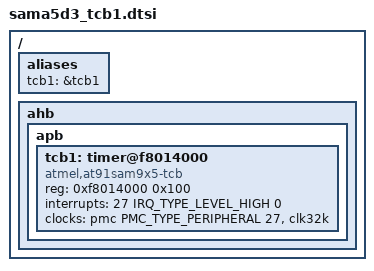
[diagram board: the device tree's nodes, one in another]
// SPDX-License-Identifier: GPL-2.0-only
/*
 * sama5d3_tcb1.dtsi - Device Tree Include file for SAMA5D3 SoC with
 * 2 TC blocks.
 *
 * Copyright (C) 2013 Boris BREZILLON <b.brezillon@overkiz.com>
 */

#include <dt-bindings/pinctrl/at91.h>
#include <dt-bindings/interrupt-controller/irq.h>
#include <dt-bindings/clock/at91.h>

/ {
	aliases {
		tcb1 = &tcb1;
	};

	ahb {
		apb {
			tcb1: timer@f8014000 {
				compatible = "atmel,at91sam9x5-tcb", "simple-mfd", "syscon";
				#address-cells = <1>;
				#size-cells = <0>;
				reg = <0xf8014000 0x100>;
				interrupts = <27 IRQ_TYPE_LEVEL_HIGH 0>;
				clocks = <&pmc PMC_TYPE_PERIPHERAL 27>, <&clk32k>;
				clock-names = "t0_clk", "slow_clk";
			};
		};
	};
};
